# STM32H730 register map
File version: 1.9
CPU: CM7 r0p1, little endian, MPU, FPU, 4 interrupt priority bits
Registers are 32-bit, read-write, reset 0x0 unless marked. A register's access mark holds for its fields unless they carry their own. Offsets are from the block's base; [hi:lo] are bit positions.

## SWPMI — Single Wire Protocol Master Interface
Base 0x40008800
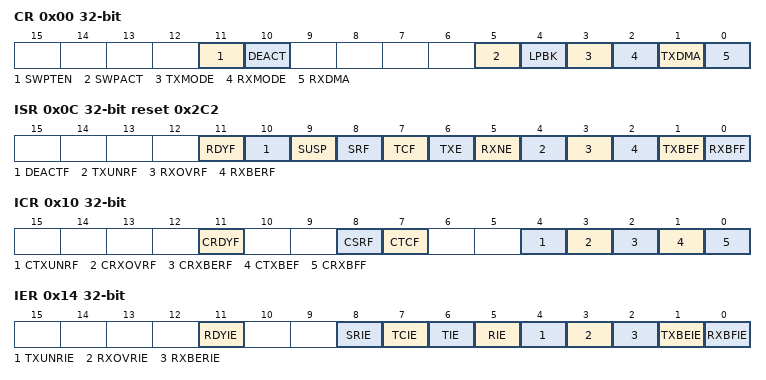
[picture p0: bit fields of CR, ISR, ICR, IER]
0x00 CR — SWPMI Configuration/Control register
  [11] SWPTEN — Single wire protocol master transceiver enable
  [10] DEACT — Single wire protocol master interface deactivate
  [5] SWPACT — Single wire protocol master interface activate
  [4] LPBK — Loopback mode enable
  [3] TXMODE — Transmission buffering mode
  [2] RXMODE — Reception buffering mode
  [1] TXDMA — Transmission DMA enable
  [0] RXDMA — Reception DMA enable
0x04 BRR reset 0x1 — SWPMI Bitrate register
  [7:0] BR — Bitrate prescaler
0x0C ISR ro reset 0x2C2 — SWPMI Interrupt and Status register
  [11] RDYF — transceiver ready flag
  [10] DEACTF — DEACTIVATED flag
  [9] SUSP — SUSPEND flag
  [8] SRF — Slave resume flag
  [7] TCF — Transfer complete flag
  [6] TXE — Transmit data register empty
  [5] RXNE — Receive data register not empty
  [4] TXUNRF — Transmit underrun error flag
  [3] RXOVRF — Receive overrun error flag
  [2] RXBERF — Receive CRC error flag
  [1] TXBEF — Transmit buffer empty flag
  [0] RXBFF — Receive buffer full flag
0x10 ICR wo — SWPMI Interrupt Flag Clear register
  [11] CRDYF — Clear transceiver ready flag
  [8] CSRF — Clear slave resume flag
  [7] CTCF — Clear transfer complete flag
  [4] CTXUNRF — Clear transmit underrun error flag
  [3] CRXOVRF — Clear receive overrun error flag
  [2] CRXBERF — Clear receive CRC error flag
  [1] CTXBEF — Clear transmit buffer empty flag
  [0] CRXBFF — Clear receive buffer full flag
0x14 IER — SWPMI Interrupt Enable register
  [11] RDYIE — Transceiver ready interrupt enable
  [8] SRIE — Slave resume interrupt enable
  [7] TCIE — Transmit complete interrupt enable
  [6] TIE — Transmit interrupt enable
  [5] RIE — Receive interrupt enable
  [4] TXUNRIE — Transmit underrun error interrupt enable
  [3] RXOVRIE — Receive overrun error interrupt enable
  [2] RXBERIE — Receive CRC error interrupt enable
  [1] TXBEIE — Transmit buffer empty interrupt enable
  [0] RXBFIE — Receive buffer full interrupt enable
0x18 RFL ro — SWPMI Receive Frame Length register
  [4:0] RFL — Receive frame length
0x1C TDR wo — SWPMI Transmit data register
  [31:0] TD — Transmit data
0x20 RDR ro — SWPMI Receive data register
  [31:0] RD — received data
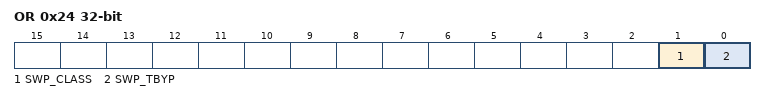
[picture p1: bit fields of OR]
0x24 OR — SWPMI Option register
  [1] SWP_CLASS — SWP class selection
  [0] SWP_TBYP — SWP transceiver bypass

## TIM6 — Basic timers
Base 0x40001000
Same registers: TIM7 0x40001400
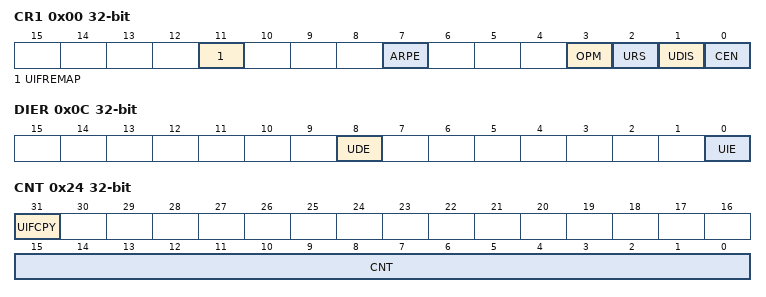
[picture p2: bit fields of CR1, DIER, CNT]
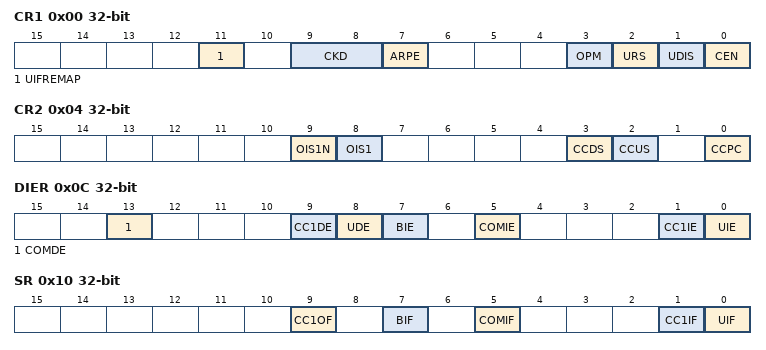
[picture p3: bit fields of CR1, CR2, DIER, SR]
0x00 CR1 — control register 1
  [11] UIFREMAP — UIF status bit remapping
  [7] ARPE — Auto-reload preload enable
  [3] OPM — One-pulse mode
  [2] URS — Update request source
  [1] UDIS — Update disable
  [0] CEN — Counter enable
0x04 CR2 — control register 2
  [6:4] MMS — Master mode selection
0x0C DIER — DMA/Interrupt enable register
  [8] UDE — Update DMA request enable
  [0] UIE — Update interrupt enable
0x10 SR — status register
  [0] UIF — Update interrupt flag
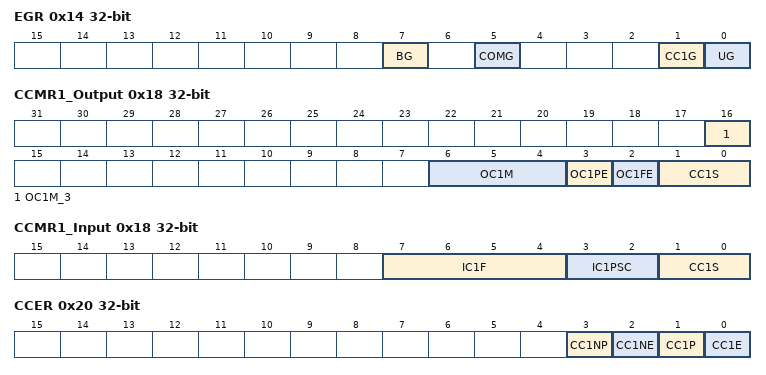
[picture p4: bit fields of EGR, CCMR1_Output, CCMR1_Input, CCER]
0x14 EGR wo — event generation register
  [0] UG — Update generation
0x24 CNT — counter
  [31] UIFCPY — UIF Copy
  [15:0] CNT — Low counter value
0x28 PSC — prescaler
  [15:0] PSC — Prescaler value
0x2C ARR — auto-reload register
  [15:0] ARR — Low Auto-reload value

## TIM16 — General-purpose-timers
Base 0x40014400
0x00 CR1 — control register 1
  [11] UIFREMAP — UIF status bit remapping
  [9:8] CKD — Clock division
  [7] ARPE — Auto-reload preload enable
  [3] OPM — One-pulse mode
  [2] URS — Update request source
  [1] UDIS — Update disable
  [0] CEN — Counter enable
0x04 CR2 — control register 2
  [9] OIS1N — Output Idle state 1
  [8] OIS1 — Output Idle state 1
  [3] CCDS — Capture/compare DMA selection
  [2] CCUS — Capture/compare control update selection
  [0] CCPC — Capture/compare preloaded control
0x0C DIER — DMA/Interrupt enable register
  [13] COMDE — COM DMA request enable
  [9] CC1DE — Capture/Compare 1 DMA request enable
  [8] UDE — Update DMA request enable
  [7] BIE — Break interrupt enable
  [5] COMIE — COM interrupt enable
  [1] CC1IE — Capture/Compare 1 interrupt enable
  [0] UIE — Update interrupt enable
0x10 SR — status register
  [9] CC1OF — Capture/Compare 1 overcapture flag
  [7] BIF — Break interrupt flag
  [5] COMIF — COM interrupt flag
  [1] CC1IF — Capture/compare 1 interrupt flag
  [0] UIF — Update interrupt flag
0x14 EGR wo — event generation register
  [7] BG — Break generation
  [5] COMG — Capture/Compare control update generation
  [1] CC1G — Capture/compare 1 generation
  [0] UG — Update generation
0x18 CCMR1_Output — capture/compare mode register (output mode)
  [16] OC1M_3 — Output Compare 1 mode
  [6:4] OC1M — Output Compare 1 mode
  [3] OC1PE — Output Compare 1 preload enable
  [2] OC1FE — Output Compare 1 fast enable
  [1:0] CC1S — Capture/Compare 1 selection
0x18 CCMR1_Input (alternate view of CCMR1_Output) — capture/compare mode register 1 (input mode)
  [7:4] IC1F — Input capture 1 filter
  [3:2] IC1PSC — Input capture 1 prescaler
  [1:0] CC1S — Capture/Compare 1 selection
0x20 CCER — capture/compare enable register
  [3] CC1NP — Capture/Compare 1 output Polarity
  [2] CC1NE — Capture/Compare 1 complementary output enable
  [1] CC1P — Capture/Compare 1 output Polarity
  [0] CC1E — Capture/Compare 1 output enable
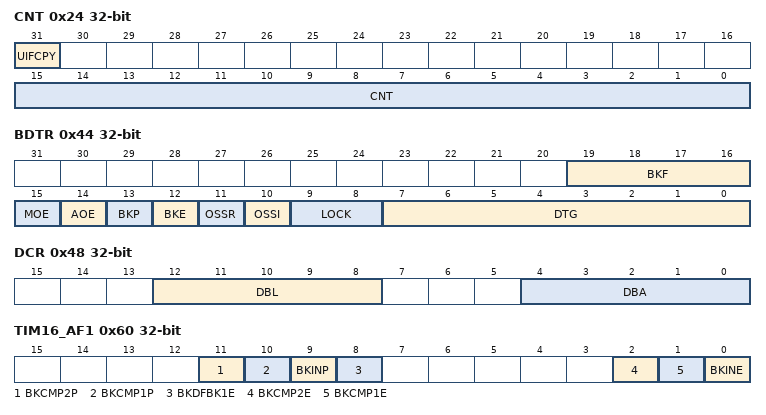
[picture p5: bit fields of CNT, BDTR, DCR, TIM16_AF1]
0x24 CNT access per field — counter
  [31] UIFCPY ro — UIF Copy
  [15:0] CNT rw — counter value
0x28 PSC — prescaler
  [15:0] PSC — Prescaler value
0x2C ARR — auto-reload register
  [15:0] ARR — Auto-reload value
0x30 RCR — repetition counter register
  [7:0] REP — Repetition counter value
0x34 CCR1 — capture/compare register 1
  [15:0] CCR1 — Capture/Compare 1 value
0x44 BDTR — break and dead-time register
  [19:16] BKF — Break filter
  [15] MOE — Main output enable
  [14] AOE — Automatic output enable
  [13] BKP — Break polarity
  [12] BKE — Break enable
  [11] OSSR — Off-state selection for Run mode
  [10] OSSI — Off-state selection for Idle mode
  [9:8] LOCK — Lock configuration
  [7:0] DTG — Dead-time generator setup
0x48 DCR — DMA control register
  [12:8] DBL — DMA burst length
  [4:0] DBA — DMA base address
0x4C DMAR — DMA address for full transfer
  [15:0] DMAB — DMA register for burst accesses
0x60 TIM16_AF1 — TIM16 alternate function register 1
  [11] BKCMP2P — BRK COMP2 input polarity
  [10] BKCMP1P — BRK COMP1 input polarity
  [9] BKINP — BRK BKIN input polarity
  [8] BKDFBK1E — BRK dfsdm1_break[1] enable
  [2] BKCMP2E — BRK COMP2 enable
  [1] BKCMP1E — BRK COMP1 enable
  [0] BKINE — BRK BKIN input enable
0x68 TIM16_TISEL — TIM16 input selection register
  [3:0] TI1SEL — selects TI1[0] to TI1[15] input

## TIM17 — General-purpose-timers
Base 0x40014800
Registers as TIM16 (with TIM16 read as TIM17).

## VREFBUF
Base 0x58003C00
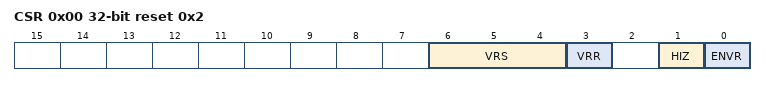
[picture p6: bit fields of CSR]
0x00 CSR access per field reset 0x2 — VREFBUF control and status register
  [6:4] VRS rw — Voltage reference scale These bits select the value generated by the voltage reference buffer. Other: Reserved
  [3] VRR ro — Voltage reference buffer ready
  [1] HIZ rw — High impedance mode This bit controls the analog switch to connect or not the VREF+ pin. Refer to Table196: VREF buffer modes for the mode descriptions depending on ENVR bit configuration.
  [0] ENVR rw — Voltage reference buffer mode enable This bit is used to enable the voltage reference buffer mode.
0x04 CCR — VREFBUF calibration control register
  [5:0] TRIM — Trimming code These bits are automatically initialized after reset with the trimming value stored in the Flash memory during the production test. Writing into these bits allows to tune the internal reference buffer voltage.

## WWDG1 — WWDG
Base 0x50003000
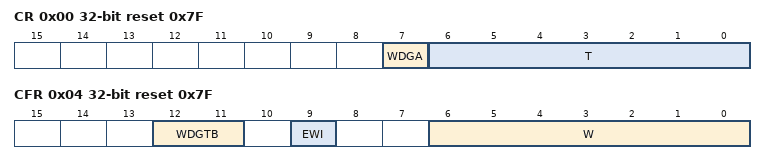
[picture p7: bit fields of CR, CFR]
0x00 CR reset 0x7F — Control register
  [7] WDGA — Activation bit This bit is set by software and only cleared by hardware after a reset. When WDGA=1, the watchdog can generate a reset.
  [6:0] T — 7-bit counter (MSB to LSB) These bits contain the value of the watchdog counter. It is decremented every (4096 x 2WDGTB[1:0]) PCLK cycles. A reset is produced when it is decremented from 0x40 to 0x3F (T6 becomes cleared).
0x04 CFR reset 0x7F — Configuration register
  [12:11] WDGTB — Timer base The time base of the prescaler can be modified as follows:
  [9] EWI — Early wakeup interrupt When set, an interrupt occurs whenever the counter reaches the value 0x40. This interrupt is only cleared by hardware after a reset.
  [6:0] W — 7-bit window value These bits contain the window value to be compared to the downcounter.
0x08 SR — Status register
  [0] EWIF — Early wakeup interrupt flag This bit is set by hardware when the counter has reached the value 0x40. It must be cleared by software by writing 0. A write of 1 has no effect. This bit is also set if the interrupt is not enabled.
